# d register map
File version: 1
test description
Registers are 32-bit, read-write, reset 0x0 unless marked. A register's access mark holds for its fields unless they carry their own. Offsets are from the block's base; lines under a group give offsets from that group; [hi:lo] are bit positions; {n}, {i} and the like mark numbered series; 'fields as' and 'values as' point back to an identical list; <NAME> marks a mode.

## Memory map
0x00000000 p1
0x00000100 p2
0x00000200 p3
0x00000300 p4
0x00000400 p5

## p1
Base 0x00000000
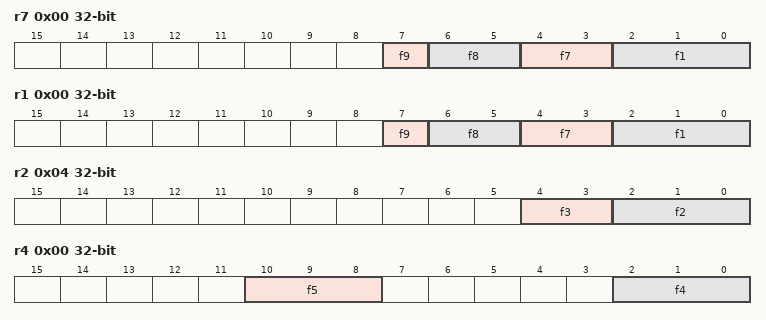
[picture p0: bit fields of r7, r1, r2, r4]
0x00 r7
  [7] f9 — test
  [6:5] f8 — test
  [4:3] f7 — test
  [2:0] f1 — test
0x04 cl1 group — test
  0x00 r1
    [7] f9 — test
    [6:5] f8 — test
    [4:3] f7 — test
    [2:0] f1 — test
  0x04 r2
    [4:3] f3, [2:0] f2
0x0C r8
0x10 cl2 group — test
  0x00 r3
  0x00 cl3 group — test
    0x00 r4
      [10:8] f5, [2:0] f4
0x14 r9

## p2
Base 0x00000100
Same registers: p3 0x00000200
0x00 r5 192-bit
  [7] f9 — test
  [6:5] f8 — test
  [4:3] f7 — test
  [2:0] f6 — test

## p4
Base 0x00000300
Same registers: p5 0x00000400
0x00 cl4 group — test
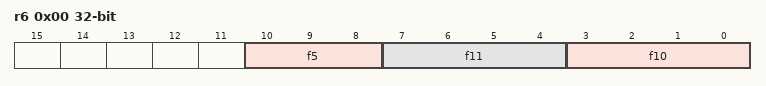
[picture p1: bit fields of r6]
  0x00 r6
    [10:8] f5, [7:4] f11, [3:0] f10
0x01 cl5 group — test
  0x00 r6
    [10:8] f5, [7:4] f11, [3:0] f10
